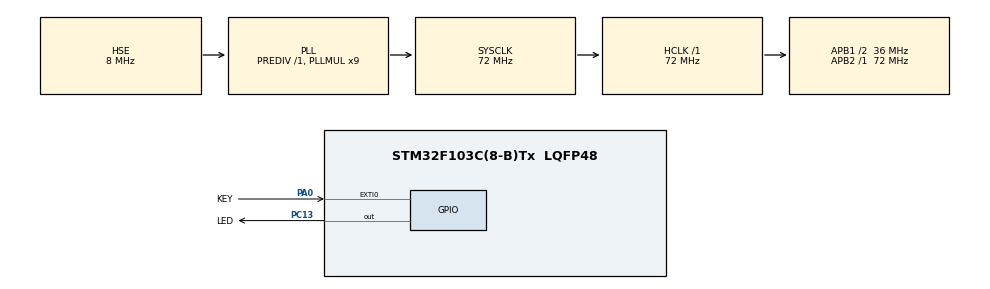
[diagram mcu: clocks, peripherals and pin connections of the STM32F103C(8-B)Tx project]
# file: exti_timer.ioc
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Mcu.Family=STM32F1
Mcu.Name=STM32F103C(8-B)Tx
Mcu.Package=LQFP48
NVIC.EXTI0_IRQn=true\:1\:0\:true\:false\:true\:true\:true\:true
NVIC.PriorityGroup=NVIC_PRIORITYGROUP_4
NVIC.TIM3_IRQn=true\:0\:0\:false\:false\:true\:true\:true\:true
PA0-WKUP.GPIO_Label=KEY
PA0-WKUP.GPIO_ModeDefaultEXTI=GPIO_MODE_IT_FALLING
PA0-WKUP.GPIO_PuPd=GPIO_PULLUP
PA0-WKUP.Signal=GPXTI0
PA13.Mode=Serial_Wire
PA13.Signal=SYS_JTMS-SWDIO
PA14.Mode=Serial_Wire
PA14.Signal=SYS_JTCK-SWCLK
PC13-TAMPER-RTC.GPIO_Label=LED
PC13-TAMPER-RTC.PinState=GPIO_PIN_SET
PC13-TAMPER-RTC.Signal=GPIO_Output
PD0-OSC_IN.Mode=HSE-External-Oscillator
PD0-OSC_IN.Signal=RCC_OSC_IN
PD1-OSC_OUT.Mode=HSE-External-Oscillator
PD1-OSC_OUT.Signal=RCC_OSC_OUT
ProjectManager.HeapSize=0x200
ProjectManager.StackSize=0x400
ProjectManager.TargetToolchain=CMake
RCC.AHBFreq_Value=72000000
RCC.APB1CLKDivider=RCC_HCLK_DIV2
RCC.APB1Freq_Value=36000000
RCC.APB1TimFreq_Value=72000000
RCC.APB2Freq_Value=72000000
RCC.APB2TimFreq_Value=72000000
RCC.HCLKFreq_Value=72000000
RCC.PLLMUL=RCC_PLL_MUL9
RCC.PLLSourceVirtual=RCC_PLLSOURCE_HSE
RCC.SYSCLKFreq_VALUE=72000000
RCC.SYSCLKSource=RCC_SYSCLKSOURCE_PLLCLK
RCC.USBFreq_Value=72000000
TIM3.AutoReloadPreload=TIM_AUTORELOAD_PRELOAD_ENABLE
TIM3.Period=999
TIM3.Prescaler=71
VP_TIM3_VS_ClockSourceINT.Mode=Internal
board=custom

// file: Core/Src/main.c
/* USER CODE BEGIN Header */
/**
  ******************************************************************************
  * @file          main.c
  * @brief         Timer 1ms系统节拍 + EXTI按键中断 + 非阻塞LED闪烁
  * @par firmware: STM32F103 HAL (STM32CubeMX)
  * @date          2026-10-25
  * @note          按键：EXTI下降沿中断 + 消抖锁定事件计数；
  *                LED：基于节拍的500ms非阻塞闪烁。
  ******************************************************************************
  * @attention
  *
  * Copyright (c) 2026 STMicroelectronics.
  * All rights reserved.
  *
  * This software is licensed under terms that can be found in the LICENSE file
  * in the root directory of this software component.
  * If no LICENSE file comes with this software, it is provided AS-IS.
  *
  ******************************************************************************
  */
/* USER CODE END Header */
#include "main.h"
#include "tim.h"
#include "gpio.h"

/* USER CODE BEGIN Includes */
#include "app_config.h"
#include "bsp_led.h"
#include "bsp_key.h"
#include "drv_timer_tick.h"
/* USER CODE END Includes */

void SystemClock_Config(void);

int main(void)
{

  /* MCU Configuration--------------------------------------------------------*/

  /* Reset of all peripherals, Initializes the Flash interface and the Systick. */
  HAL_Init();

  /* Configure the system clock */
  SystemClock_Config();

  /* Initialize all configured peripherals */
  MX_GPIO_Init();
  MX_TIM3_Init();
  /* USER CODE BEGIN 2 */
  drv_timer_tick_init();
  LED_Init();
  KEY_Init();

  uint32_t led_last_tick = 0;
  uint32_t key_event_count_last = 0;
  /* USER CODE END 2 */

  /* Infinite loop */
  while (1)
  {

    /* USER CODE BEGIN 3 */

    /*
     * 读取共享变量时，先取局部快照，
     * 避免一次逻辑中多次读取到不同值。
     */
    uint32_t now = drv_timer_tick_get();
    uint32_t key_event_count_snapshot = KEY_GetEventCount();

    /*
     * 按键事件处理：产生按键事件时立即翻转 LED 并重置闪烁节拍
     */
    if (key_event_count_snapshot != key_event_count_last)
    {
      key_event_count_last = key_event_count_snapshot;

      LED_Toggle();
      led_last_tick = now;
    }

    /*
     * 非阻塞 LED 闪烁：500ms 一次
     */
    if ((uint32_t)(now - led_last_tick) >= LED_BLINK_PERIOD_MS)
    {
      led_last_tick = now;
      LED_Toggle();
    }
  }
  /* USER CODE END 3 */
}

void SystemClock_Config(void)
{
  RCC_OscInitTypeDef RCC_OscInitStruct = {0};
  RCC_ClkInitTypeDef RCC_ClkInitStruct = {0};

  /** Initializes the RCC Oscillators according to the specified parameters
  * in the RCC_OscInitTypeDef structure.
  */
  RCC_OscInitStruct.OscillatorType = RCC_OSCILLATORTYPE_HSE;
  RCC_OscInitStruct.HSEState = RCC_HSE_ON;
  RCC_OscInitStruct.HSEPredivValue = RCC_HSE_PREDIV_DIV1;
  RCC_OscInitStruct.HSIState = RCC_HSI_ON;
  RCC_OscInitStruct.PLL.PLLState = RCC_PLL_ON;
  RCC_OscInitStruct.PLL.PLLSource = RCC_PLLSOURCE_HSE;
  RCC_OscInitStruct.PLL.PLLMUL = RCC_PLL_MUL9;
  if (HAL_RCC_OscConfig(&RCC_OscInitStruct) != HAL_OK)
  {
    Error_Handler();
  }

  /** Initializes the CPU, AHB and APB buses clocks
  */
  RCC_ClkInitStruct.ClockType = RCC_CLOCKTYPE_HCLK|RCC_CLOCKTYPE_SYSCLK
                              |RCC_CLOCKTYPE_PCLK1|RCC_CLOCKTYPE_PCLK2;
  RCC_ClkInitStruct.SYSCLKSource = RCC_SYSCLKSOURCE_PLLCLK;
  RCC_ClkInitStruct.AHBCLKDivider = RCC_SYSCLK_DIV1;
  RCC_ClkInitStruct.APB1CLKDivider = RCC_HCLK_DIV2;
  RCC_ClkInitStruct.APB2CLKDivider = RCC_HCLK_DIV1;

  if (HAL_RCC_ClockConfig(&RCC_ClkInitStruct, FLASH_LATENCY_2) != HAL_OK)
  {
    Error_Handler();
  }
}

void Error_Handler(void)
{
  __disable_irq();
  while (1)
  {
  }
}
